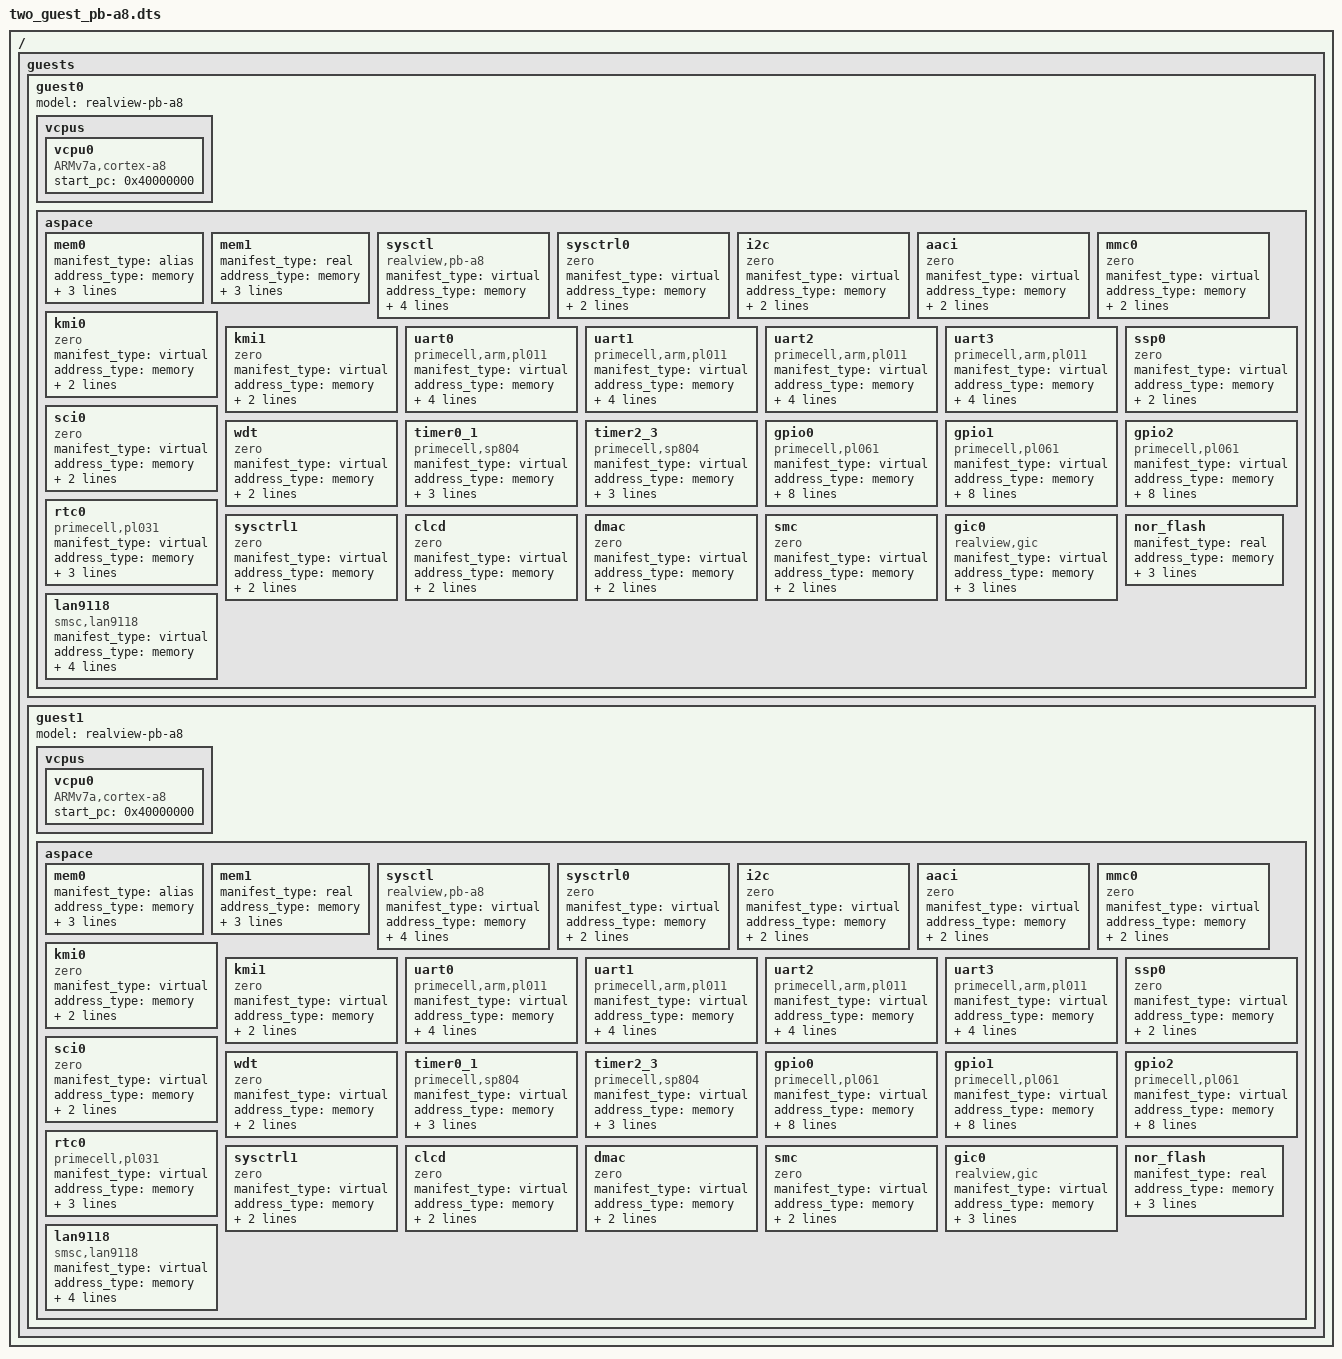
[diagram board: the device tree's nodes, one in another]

/dts-v1/;

/include/ "beagle.dtsi"

/ {
	guests {
		guest0 {
			model = "realview-pb-a8";
			device_type = "guest";

			vcpus {
				vcpu0 {
					device_type = "vcpu";
					compatible = "ARMv7a,cortex-a8";
					start_pc = <0x40000000>;
				};
			};
			
			aspace {
				mem0 {
					manifest_type = "alias";
					address_type = "memory";
					guest_physical_addr = <0x00000000>;
					alias_physical_addr = <0x70000000>;
					physical_size = <0x06000000>; /* 96 MB */
					device_type = "ram";
				};

				mem1 {
					manifest_type = "real";
					address_type = "memory";
					guest_physical_addr = <0x70000000>;
					host_physical_addr = <0x8a000000>;
					physical_size = <0x06000000>; /* 96 MB */
					device_type = "ram";
				};

				sysctl {
					manifest_type = "virtual";
					address_type = "memory";
					guest_physical_addr = <0x10000000>;
					physical_size = <0x1000>;
					device_type = "sys";
					compatible = "realview,pb-a8";
					mux_in_irq = <2000 2001>;
					mux_out_irq = <2002>;
				};

				sysctrl0 { /* No SP810 sysctrl */
					manifest_type = "virtual";
					address_type = "memory";
					guest_physical_addr = <0x10001000>;
					physical_size = <0x1000>;
					device_type = "misc";
					compatible = "zero";
				};

				i2c { /* No I2C */
					manifest_type = "virtual";
					address_type = "memory";
					guest_physical_addr = <0x10002000>;
					physical_size = <0x1000>;
					device_type = "misc";
					compatible = "zero";
				};

				aaci { /* No Audio Controller */
					manifest_type = "virtual";
					address_type = "memory";
					guest_physical_addr = <0x10004000>;
					physical_size = <0x1000>;
					device_type = "misc";
					compatible = "zero";
				};

				mmc0 { /* No Multimedia Card Interface */
					manifest_type = "virtual";
					address_type = "memory";
					guest_physical_addr = <0x10005000>;
					physical_size = <0x1000>;
					device_type = "misc";
					compatible = "zero";
				};

				kmi0 { /* No Keyboard/Mouse Interface */
					manifest_type = "virtual";
					address_type = "memory";
					guest_physical_addr = <0x10006000>;
					physical_size = <0x1000>;
					device_type = "misc";
					compatible = "zero";
				};

				kmi1 { /* No Keyboard/Mouse Interface */
					manifest_type = "virtual";
					address_type = "memory";
					guest_physical_addr = <0x10007000>;
					physical_size = <0x1000>;
					device_type = "misc";
					compatible = "zero";
 				};
 
				uart0 {
					manifest_type = "virtual";
					address_type = "memory";
					guest_physical_addr = <0x10009000>;
					physical_size = <0x1000>;
					device_type = "serial";
					compatible = "primecell,arm,pl011";
					fifo_size = <1024>;
					irq = <44>;
				};

				uart1 {
					manifest_type = "virtual";
					address_type = "memory";
					guest_physical_addr = <0x1000A000>;
					physical_size = <0x1000>;
					device_type = "serial";
					compatible = "primecell,arm,pl011";
					fifo_size = <1024>;
					irq = <45>;
				};

				uart2 {
					manifest_type = "virtual";
					address_type = "memory";
					guest_physical_addr = <0x1000B000>;
					physical_size = <0x1000>;
					device_type = "serial";
					compatible = "primecell,arm,pl011";
					fifo_size = <1024>;
					irq = <46>;
				};

				uart3 {
					manifest_type = "virtual";
					address_type = "memory";
					guest_physical_addr = <0x1000C000>;
					physical_size = <0x1000>;
					device_type = "serial";
					compatible = "primecell,arm,pl011";
					fifo_size = <1024>;
					irq = <47>;
				};

				ssp0 { /* No Synchronous Serial Port */
					manifest_type = "virtual";
					address_type = "memory";
					guest_physical_addr = <0x1000D000>;
					physical_size = <0x1000>;
					device_type = "misc";
					compatible = "zero";
				};

				sci0 { /* No Smart card controller */
					manifest_type = "virtual";
					address_type = "memory";
					guest_physical_addr = <0x1000E000>;
					physical_size = <0x1000>;
					device_type = "misc";
					compatible = "zero";
				};

				wdt { /* No Watch-Dog controller */
					manifest_type = "virtual";
					address_type = "memory";
					guest_physical_addr = <0x10010000>;
					physical_size = <0x1000>;
					device_type = "misc";
					compatible = "zero";
				};

				timer0_1 {
					manifest_type = "virtual";
					address_type = "memory";
					guest_physical_addr = <0x10011000>;
					physical_size = <0x1000>;
					device_type = "timer";
					compatible = "primecell,sp804";
					irq = <36>;
				};

				timer2_3 {
					manifest_type = "virtual";
					address_type = "memory";
					guest_physical_addr = <0x10012000>;
					physical_size = <0x1000>;
					device_type = "timer";
					compatible = "primecell,sp804";
					irq = <37>;
				};

				gpio0 {
					manifest_type = "virtual";
					address_type = "memory";
					guest_physical_addr = <0x10013000>;
					physical_size = <0x1000>;
					device_type = "gpio";
					compatible = "primecell,pl061";
					gpio_in_invert = <0 0 0 0 0 0 0 0>;
					gpio_in_irq = <4000 4001 4002 4003 4004 4005 4006 4007>;
					gpio_out_irq = <4008 4009 4010 4011 4012 4013 4014 4015>;
					irq = <38>;
				};

				gpio1 {
					manifest_type = "virtual";
					address_type = "memory";
					guest_physical_addr = <0x10014000>;
					physical_size = <0x1000>;
					device_type = "gpio";
					compatible = "primecell,pl061";
					gpio_in_invert = <0 0 0 0 0 0 0 0>;
					gpio_in_irq = <3000 3001 3002 3003 3004 3005 3006 3007>;
					gpio_out_irq = <3008 3009 3010 3011 3012 3013 3014 3015>;
					irq = <39>;
				};

				gpio2 {
					manifest_type = "virtual";
					address_type = "memory";
					guest_physical_addr = <0x10015000>;
					physical_size = <0x1000>;
					device_type = "gpio";
					compatible = "primecell,pl061";
					gpio_in_invert = <1 0 0 0 0 0 0 0>;
					gpio_in_irq = <2001 2000 2002 2003 2004 2005 2006 2007>;
					gpio_out_irq = <2008 2009 2010 2011 2012 2013 2014 2015>;
					irq = <40>;
				};

				rtc0 {
					manifest_type = "virtual";
					address_type = "memory";
					guest_physical_addr = <0x10017000>;
					physical_size = <0x1000>;
					device_type = "rtc";
					compatible = "primecell,pl031";
					irq = <42>;
				};

				sysctrl1 { /* No SP810 sysctrl */
					manifest_type = "virtual";
					address_type = "memory";
					guest_physical_addr = <0x1001A000>;
					physical_size = <0x1000>;
					device_type = "misc";
					compatible = "zero";
				};

				clcd { /* No Color LCD */
					manifest_type = "virtual";
					address_type = "memory";
					guest_physical_addr = <0x10020000>;
					physical_size = <0x1000>;
					device_type = "misc";
					compatible = "zero";
				};

				dmac { /* No DMA Controller */
					manifest_type = "virtual";
					address_type = "memory";
					guest_physical_addr = <0x10030000>;
					physical_size = <0x1000>;
					device_type = "misc";
					compatible = "zero";
				};

				smc { /* No SMC */
					manifest_type = "virtual";
					address_type = "memory";
					guest_physical_addr = <0x100E1000>;
					physical_size = <0x1000>;
					device_type = "misc";
					compatible = "zero";
 				};
 
				gic0 {
					manifest_type = "virtual";
					address_type = "memory";
					guest_physical_addr = <0x1E000000>;
					physical_size = <0x2000>;
					device_type = "pic";
					compatible = "realview,gic";
					parent_irq = <6>;
				};

				nor_flash {
					manifest_type = "real";
					address_type = "memory";
					guest_physical_addr = <0x40000000>;
					host_physical_addr = <0x89000000>;
					physical_size = <0x01000000>; /* 16 MB */
					device_type = "rom";
				};

				lan9118 { /* Ethernet Controller */
					manifest_type = "virtual";
					address_type = "memory";
					guest_physical_addr = <0x4E000000>;
					physical_size = <0x10000>;
					device_type = "nic";
					compatible = "smsc,lan9118";
					switch = "netbridge0";
					irq = <60>;
				};
			};
		};

		guest1 {
			model = "realview-pb-a8";
			device_type = "guest";

			vcpus {
				vcpu0 {
					device_type = "vcpu";
					compatible = "ARMv7a,cortex-a8";
					start_pc = <0x40000000>;
				};
			};
			
			aspace {
				mem0 {
					manifest_type = "alias";
					address_type = "memory";
					guest_physical_addr = <0x00000000>;
					alias_physical_addr = <0x70000000>;
					physical_size = <0x06000000>; /* 96 MB */
					device_type = "ram";
				};

				mem1 {
					manifest_type = "real";
					address_type = "memory";
					guest_physical_addr = <0x70000000>;
					host_physical_addr = <0x91000000>;
					physical_size = <0x06000000>; /* 96 MB */
					device_type = "ram";
				};

				sysctl {
					manifest_type = "virtual";
					address_type = "memory";
					guest_physical_addr = <0x10000000>;
					physical_size = <0x1000>;
					device_type = "sys";
					compatible = "realview,pb-a8";
					mux_in_irq = <2000 2001>;
					mux_out_irq = <2002>;
				};

				sysctrl0 { /* No SP810 sysctrl */
					manifest_type = "virtual";
					address_type = "memory";
					guest_physical_addr = <0x10001000>;
					physical_size = <0x1000>;
					device_type = "misc";
					compatible = "zero";
				};

				i2c { /* No I2C */
					manifest_type = "virtual";
					address_type = "memory";
					guest_physical_addr = <0x10002000>;
					physical_size = <0x1000>;
					device_type = "misc";
					compatible = "zero";
				};

				aaci { /* No Audio Controller */
					manifest_type = "virtual";
					address_type = "memory";
					guest_physical_addr = <0x10004000>;
					physical_size = <0x1000>;
					device_type = "misc";
					compatible = "zero";
				};

				mmc0 { /* No Multimedia Card Interface */
					manifest_type = "virtual";
					address_type = "memory";
					guest_physical_addr = <0x10005000>;
					physical_size = <0x1000>;
					device_type = "misc";
					compatible = "zero";
				};

				kmi0 { /* No Keyboard/Mouse Interface */
					manifest_type = "virtual";
					address_type = "memory";
					guest_physical_addr = <0x10006000>;
					physical_size = <0x1000>;
					device_type = "misc";
					compatible = "zero";
				};

				kmi1 { /* No Keyboard/Mouse Interface */
					manifest_type = "virtual";
					address_type = "memory";
					guest_physical_addr = <0x10007000>;
					physical_size = <0x1000>;
					device_type = "misc";
					compatible = "zero";
 				};
 
				uart0 {
					manifest_type = "virtual";
					address_type = "memory";
					guest_physical_addr = <0x10009000>;
					physical_size = <0x1000>;
					device_type = "serial";
					compatible = "primecell,arm,pl011";
					fifo_size = <1024>;
					irq = <44>;
				};

				uart1 {
					manifest_type = "virtual";
					address_type = "memory";
					guest_physical_addr = <0x1000A000>;
					physical_size = <0x1000>;
					device_type = "serial";
					compatible = "primecell,arm,pl011";
					fifo_size = <1024>;
					irq = <45>;
				};

				uart2 {
					manifest_type = "virtual";
					address_type = "memory";
					guest_physical_addr = <0x1000B000>;
					physical_size = <0x1000>;
					device_type = "serial";
					compatible = "primecell,arm,pl011";
					fifo_size = <1024>;
					irq = <46>;
				};

				uart3 {
					manifest_type = "virtual";
					address_type = "memory";
					guest_physical_addr = <0x1000C000>;
					physical_size = <0x1000>;
					device_type = "serial";
					compatible = "primecell,arm,pl011";
					fifo_size = <1024>;
					irq = <47>;
				};

				ssp0 { /* No Synchronous Serial Port */
					manifest_type = "virtual";
					address_type = "memory";
					guest_physical_addr = <0x1000D000>;
					physical_size = <0x1000>;
					device_type = "misc";
					compatible = "zero";
				};

				sci0 { /* No Smart card controller */
					manifest_type = "virtual";
					address_type = "memory";
					guest_physical_addr = <0x1000E000>;
					physical_size = <0x1000>;
					device_type = "misc";
					compatible = "zero";
				};

				wdt { /* No Watch-Dog controller */
					manifest_type = "virtual";
					address_type = "memory";
					guest_physical_addr = <0x10010000>;
					physical_size = <0x1000>;
					device_type = "misc";
					compatible = "zero";
				};

				timer0_1 {
					manifest_type = "virtual";
					address_type = "memory";
					guest_physical_addr = <0x10011000>;
					physical_size = <0x1000>;
					device_type = "timer";
					compatible = "primecell,sp804";
					irq = <36>;
				};

				timer2_3 {
					manifest_type = "virtual";
					address_type = "memory";
					guest_physical_addr = <0x10012000>;
					physical_size = <0x1000>;
					device_type = "timer";
					compatible = "primecell,sp804";
					irq = <37>;
				};

				gpio0 {
					manifest_type = "virtual";
					address_type = "memory";
					guest_physical_addr = <0x10013000>;
					physical_size = <0x1000>;
					device_type = "gpio";
					compatible = "primecell,pl061";
					gpio_in_invert = <0 0 0 0 0 0 0 0>;
					gpio_in_irq = <4000 4001 4002 4003 4004 4005 4006 4007>;
					gpio_out_irq = <4008 4009 4010 4011 4012 4013 4014 4015>;
					irq = <38>;
				};

				gpio1 {
					manifest_type = "virtual";
					address_type = "memory";
					guest_physical_addr = <0x10014000>;
					physical_size = <0x1000>;
					device_type = "gpio";
					compatible = "primecell,pl061";
					gpio_in_invert = <0 0 0 0 0 0 0 0>;
					gpio_in_irq = <3000 3001 3002 3003 3004 3005 3006 3007>;
					gpio_out_irq = <3008 3009 3010 3011 3012 3013 3014 3015>;
					irq = <39>;
				};

				gpio2 {
					manifest_type = "virtual";
					address_type = "memory";
					guest_physical_addr = <0x10015000>;
					physical_size = <0x1000>;
					device_type = "gpio";
					compatible = "primecell,pl061";
					gpio_in_invert = <1 0 0 0 0 0 0 0>;
					gpio_in_irq = <2001 2000 2002 2003 2004 2005 2006 2007>;
					gpio_out_irq = <2008 2009 2010 2011 2012 2013 2014 2015>;
					irq = <40>;
				};

				rtc0 {
					manifest_type = "virtual";
					address_type = "memory";
					guest_physical_addr = <0x10017000>;
					physical_size = <0x1000>;
					device_type = "rtc";
					compatible = "primecell,pl031";
					irq = <42>;
				};

				sysctrl1 { /* No SP810 sysctrl */
					manifest_type = "virtual";
					address_type = "memory";
					guest_physical_addr = <0x1001A000>;
					physical_size = <0x1000>;
					device_type = "misc";
					compatible = "zero";
				};

				clcd { /* No Color LCD */
					manifest_type = "virtual";
					address_type = "memory";
					guest_physical_addr = <0x10020000>;
					physical_size = <0x1000>;
					device_type = "misc";
					compatible = "zero";
				};

				dmac { /* No DMA Controller */
					manifest_type = "virtual";
					address_type = "memory";
					guest_physical_addr = <0x10030000>;
					physical_size = <0x1000>;
					device_type = "misc";
					compatible = "zero";
				};

				smc { /* No SMC */
					manifest_type = "virtual";
					address_type = "memory";
					guest_physical_addr = <0x100E1000>;
					physical_size = <0x1000>;
					device_type = "misc";
					compatible = "zero";
 				};
 
				gic0 {
					manifest_type = "virtual";
					address_type = "memory";
					guest_physical_addr = <0x1E000000>;
					physical_size = <0x2000>;
					device_type = "pic";
					compatible = "realview,gic";
					parent_irq = <6>;
				};

				nor_flash {
					manifest_type = "real";
					address_type = "memory";
					guest_physical_addr = <0x40000000>;
					host_physical_addr = <0x90000000>;
					physical_size = <0x01000000>; /* 16 MB */
					device_type = "rom";
				};

				lan9118 { /* Ethernet Controller */
					manifest_type = "virtual";
					address_type = "memory";
					guest_physical_addr = <0x4E000000>;
					physical_size = <0x10000>;
					device_type = "nic";
					compatible = "smsc,lan9118";
					switch = "netbridge0";
					irq = <60>;
				};
			};
		};
	};
};
